# RL6845_IP_SVD register map
Vendor: Realtek
Registers are 32-bit, read-write, reset 0x0 unless marked. A register's access mark holds for its fields unless they carry their own. Offsets are from the block's base; [hi:lo] are bit positions; {n}, {i} and the like mark numbered series; <NAME> marks a mode.

## psram_phy
Base 0x40126000
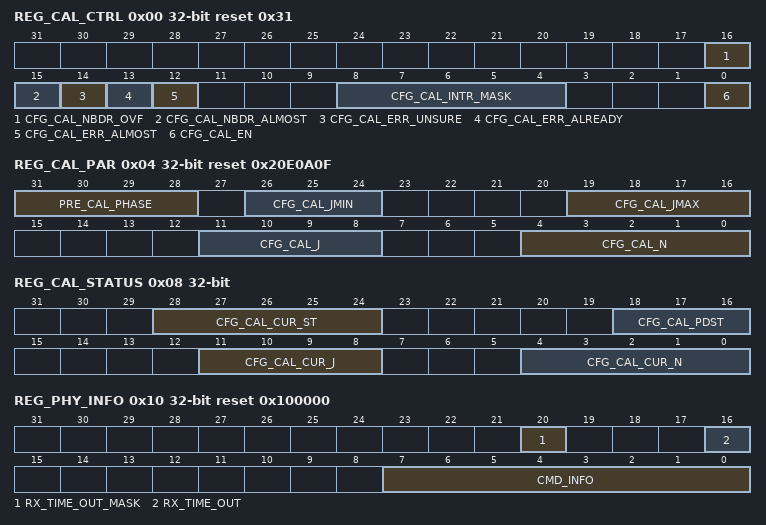
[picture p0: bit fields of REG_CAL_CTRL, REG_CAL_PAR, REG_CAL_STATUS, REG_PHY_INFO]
0x00 REG_CAL_CTRL access per field reset 0x31
  [16] CFG_CAL_NBDR_OVF ro — The N reachs the boundary , which is 0 or Nmax . Cleared by write 1 .
  [15] CFG_CAL_NBDR_ALMOST ro — The N-J or N+J reachs the boundary , which is 0 or Nmax . Cleared by write 1 .
  [14] CFG_CAL_ERR_UNSURE ro — The Pre N/J may cause current burst receive error , but it is not sure because the burst len is too small. Cleared by write 1 .
  [13] CFG_CAL_ERR_ALREADY ro — The Pre N/J may cause current burst receive error , even change J to Jmin , the error still remain . Cleared by write 1 .
  [12] CFG_CAL_ERR_ALMOST ro — The current burst receive correct , but next burst will set J = Jmin . Cleared by write 1 .
  [8:4] CFG_CAL_INTR_MASK rw — Calibration fail interrupt mask , every bit control one event above (1: enable , 0: disable) [0] : err almost [1] : err already [2] : err unsure [3] : nbdr almost [4] : nbdr ovf
  [0] CFG_CAL_EN rw — Hardware auto calibration enable , if disable , N,J will be fixed .
0x04 REG_CAL_PAR reset 0x20E0A0F
  [31:28] PRE_CAL_PHASE — one-hot phase select, 4-tap delay line to adjust rwds phase before calibration for large freq range or skew can be set to 0, bypassing the default 1-tap delay
  [26:24] CFG_CAL_JMIN — Minimum J . Hardware may adjust J , if J reach this value , an interrup will be raised to alerm software.
  [19:16] CFG_CAL_JMAX — Maximum J . Hardware may adjust J , but will not exceed this value.
  [11:8] CFG_CAL_J — Initial value J calibrated by software .
  [4:0] CFG_CAL_N — Initial value N calibrated by software .
0x08 REG_CAL_STATUS ro
  [28:24] CFG_CAL_CUR_ST — Calibration current state . Cleared by write all 1 .
  [18:16] CFG_CAL_PDST — Calibration check result for last read burst . [0] : indicate phase n+j , if 1 , means dn == dn+j [1] : indicate phase n-j , if 1 , means dn == dn-j [2] : if 1 , means the state is under j = jmin condition
  [11:8] CFG_CAL_CUR_J — Current value J read from hardware.
  [4:0] CFG_CAL_CUR_N — Current value N read from hardware.
0x10 REG_PHY_INFO access per field reset 0x100000
  [20] RX_TIME_OUT_MASK rw — read time out interrupt mask
  [16] RX_TIME_OUT ro — read time out interrupt if there's no DQS/DQ from psram, write 1 to clear
  [7:0] CMD_INFO ro — Command information, 1st Byte of Command/Address transaction
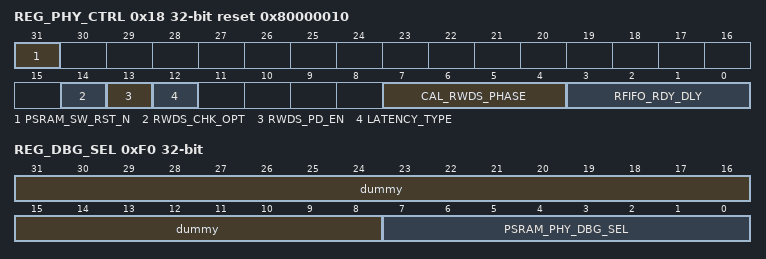
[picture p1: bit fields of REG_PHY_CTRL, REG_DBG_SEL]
0x18 REG_PHY_CTRL reset 0x80000010
  [31] PSRAM_SW_RST_N — low active, except for phy register(using system reset), psram software reset: psram, phy_ctrl, calibration
  [14] RWDS_CHK_OPT — 0: synced psram_rwds_i direct to controller 1: only check psram_rwds_i at last valid cycle of CA stage, sync this pulse to controller
  [13] RWDS_PD_EN — psram_phy can control PD pin of rwds iopad, bypass high-Z state at CMD/ADDR stage
  [12] LATENCY_TYPE — set this bit according to spic & psram latency settings 0: variable latency 1: fixed latency
  [7:4] CAL_RWDS_PHASE — one-hot phase select, delay cal_rwds to push sampling data into rfifo
  [3:0] RFIFO_RDY_DLY — variable latency: delay read data cycles(phy clk) after detecting first DQS rising edge, must < 4 fixed latency: delay read data cycles(phy clk) after asserting spi_rx_data_en, must > 5 4*read_latency - rd_dummy_length + rfifo_rdy_dly = in_physical_cyc
0xF0 REG_DBG_SEL
  [31:8] dummy
  [7:0] PSRAM_PHY_DBG_SEL — psram phy debug select signal.
0xF8 REG_DBG_INFO ro
  [31:0] PSRAM_PHY_DBG — psram phy debug signals.

## debugtimer
Base 0x41015000
0x00 DBGT_CTRL reset 0x1 — Debug Timer control register
  [0] enable — Debug timer enable. 1: The counter is enabled. 0: The counter is disabled.
0x04 DBGT_CRV — Debug Timer count register
  [31:0] dbgt_crv — Continue to count from 0 once it's reached 32'hFFFFFFFF.
0x08 DBGT_ATOM_INC ro — Debug Timer atom read increase register
  [31:0] dbgt_atom_inc — Each read will increase 1 and return to the increased value to bus.
0x0C DBGT_ATOM — Debug Timer atom register
  [31:0] dbgt_atom — Return the last increased value of atom counter.
0x10 DBGT_SCRATCH — Debug Timer scratch register
  [31:0] dbgt_scratch — Reserved
0x14 REG_DBGTIM_DUMMY reset 0xFFFF — Debug Timer Dummy Register

## pmctimer
Base 0x41016000
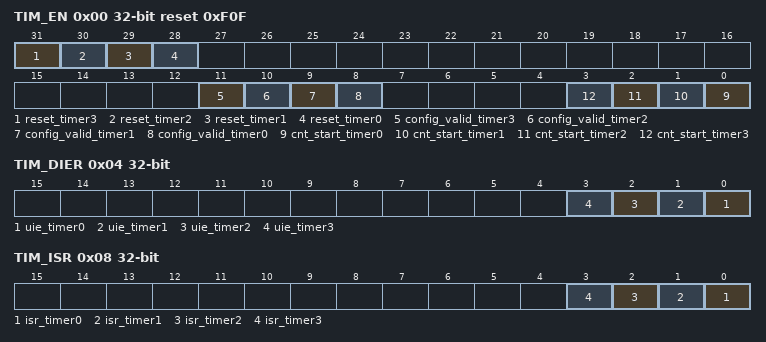
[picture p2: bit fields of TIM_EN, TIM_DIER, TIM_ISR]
0x00 TIM_EN access per field reset 0xF0F — TIM enable register
  [31] reset_timer3 wo — Writing 1 will cause a pulse reset timer1. Please wait for 3 work clk before new timer configuration 1: valid 0: not valid
  [30] reset_timer2 wo — Writing 1 will cause a pulse reset timer1. Please wait for 3 work clk before new timer configuration 1: valid 0: not valid
  [29] reset_timer1 wo — Writing 1 will cause a pulse reset timer1. Please wait for 3 work clk before new timer configuration 1: valid 0: not valid
  [28] reset_timer0 wo — Writing 1 will cause a pulse reset timer0. Please wait for 3 work clk before new timer configuration 1: valid 0: not valid
  [11] config_valid_timer3 ro — TIM_SET configuration valid or not. 1: valid 0: not valid if compare option enable, 1: vaild value is seted 0: set option is on going
  [10] config_valid_timer2 ro — TIM_SET configuration valid or not 1: valid 0: not valid
  [9] config_valid_timer1 ro — TIM_SET configuration valid or not 1: valid 0: not valid
  [8] config_valid_timer0 ro — TIM_SET configuration valid or not 1: valid 0: not valid
  [n] cnt_start_timer{n} rw (n=0..3) — enable the timer{n} counter. 1:enable 0:disable
0x04 TIM_DIER — TIM interupt enable register
  [n] uie_timer{n} (n=0..3) — 1: enable update interrupt 0: disable update interrupt
0x08 TIM_ISR ro — TIM interrupt status register
  [n] isr_timer{n} (n=0..3) — Timer interrupt status 0: no interrupt 1: interrupt occurs Write 1 to clear interrupts in interrupt handler.
{0xC+4i} TIM_CNT{i} ro reset 0xFFFFFFFF (i=0..3) — TIM counter{i}
  [31:0] cnt{i} — counter value, counter will stop automatically when it counts down to zero.
{0x1C+4i} TIM_SET{i} (i=0..3) — TIM set register{i}
  [31:0] tim_set{i} — Set a countdown value. This value come into force when TIM_EN register bit is enabled. counter will count down from this value immediately.
0x2C TIM_com_en reset 0xF — TIM compare register
  [3:0] com_en — enable compare option.The set cnt value takes effect only when it is greater than the actual cnt value 0:disable 1:enable [0] : control tim0 set ...... [3]: control tim3 set
0x30 PMCTIM_DUMMY reset 0xFFFF — PMCTimer Dummy Register

## iwdg
Base 0x41008C00
0x00 WDG_MKEYR — WDG Magic Key register
  [15:0] MKEY — 0x6969: enable access to register WDG_CR/WDG_RLR/WDG_WINR 0x5A5A: reload WDG counter 0x3C3C: enable WDG function
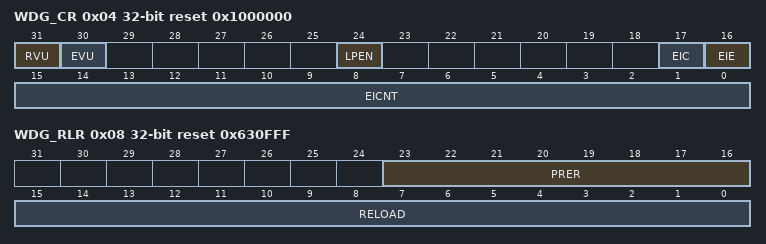
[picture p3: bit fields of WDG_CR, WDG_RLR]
0x04 WDG_CR access per field reset 0x1000000 — WDG Control regsietr
  [31] RVU ro — Watchdog counter update by reload command
  [30] EVU ro — Watchdog early interrupt function update
  [24] LPEN rw — Low power enable 0: WDG will gating when system goes into sleep mode 1: WDG keep running when system goes into sleep mode
  [17] EIC wo — Write '1' clear the early interrupt
  [16] EIE rw — Watchdog early interrupt enable
  [15:0] EICNT rw — Early interrupt trigger threshold
0x08 WDG_RLR reset 0x630FFF — WDG Relaod register
  [23:16] PRER — Prescaler counter, configuration only allowed before WDG enable IWDG: 0x63 System WDG: 0x1F
  [15:0] RELOAD — Reload value for watchdog counter
0x0C WDG_WINR reset 0xFFFF — WDG Window Register
  [15:0] WINDOW — Watchdog feed protect window register
0x10 IWDG_DUMMY reset 0xFF — WDG Dummy Register
  [15:0] dummy — Reserved for HW
